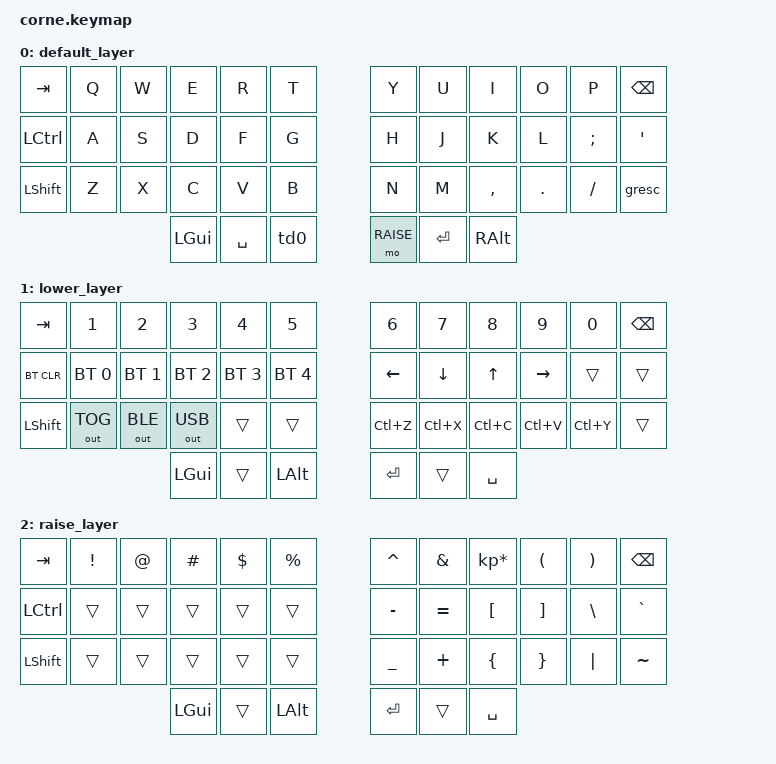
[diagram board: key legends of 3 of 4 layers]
/*
 * Copyright (c) 2020 The ZMK Contributors
 *
 * SPDX-License-Identifier: MIT
 */

#define DEFAULT 0
#define LOWER   1
#define RAISE   2
#define MOUSE   3

#include <behaviors.dtsi>
#include <dt-bindings/zmk/keys.h>
#include <dt-bindings/zmk/bt.h>
#include <dt-bindings/zmk/outputs.h>
#include <dt-bindings/zmk/mouse.h>


// -----------------------------------------------------------------------------------------
// |  0 | 1  | 2  | 3  | 4  | 5  |       | 6  |  7 | 8  | 9  | 10 | 11 |
// | 12 | 13 | 14 | 15 | 16 | 17 |       | 18 | 19 | 20 | 21 | 22 | 23 |
// | 24 | 25 | 26 | 27 | 28 | 29 |       | 30 | 31 | 32 | 33 | 34 | 35 |
//                | 36 | 37 | 38 |       | 39 | 40 | 41 |

/ {
    combos {
        compatible = "zmk,combos";
        combo_esc {
            timeout-ms = <50>;
            key-positions = <6 40>;
            bindings = <&tog MOUSE>;
        };
    };
};

/ {
        behaviors {
                td0: tap_dance_0 {
                        compatible = "zmk,behavior-tap-dance";
                        label = "TAP_DANCE_0";
                        #binding-cells = <0>;
                        tapping-term-ms = <200>;
                        bindings = <&mo LOWER>, <&mo MOUSE>, <&kp N3>;
                };
        };
    
    keymap {
                compatible = "zmk,keymap";

                default_layer {
// -----------------------------------------------------------------------------------------
// |  TAB |  Q  |  W  |  E  |  R  |  T  |       |  Y  |  U   |  I  |  O  |  P  | BKSP |
// | CTRL |  A  |  S  |  D  |  F  |  G  |       |  H  |  J   |  K  |  L  |  ;  |  '   |
// | SHFT |  Z  |  X  |  C  |  V  |  B  |       |  N  |  M   |  ,  |  .  |  /  | ESC  |
//                    | GUI | SPC | LWR |       | RSE | ENT  | ALT |
                        bindings = <
   &kp TAB   &kp Q &kp W &kp E &kp R &kp T       &kp Y &kp U  &kp I     &kp O   &kp P    &kp BSPC
   &kp LCTRL &kp A &kp S &kp D &kp F &kp G       &kp H &kp J  &kp K     &kp L   &kp SEMI &kp SQT
   &kp LSHFT &kp Z &kp X &kp C &kp V &kp B       &kp N &kp M  &kp COMMA &kp DOT &kp FSLH &gresc
		  &kp LGUI  &kp SPACE &td0       &mo RAISE &kp RET &kp RALT
                        >;
                };
                lower_layer {
// -----------------------------------------------------------------------------------------
// |  TAB |  1  |  2  |  3  |  4  |  5  |   |  6  |  7  |  8  |  9  |  0  | BKSP |
// | BTCLR| BT1 | BT2 | BT3 | BT4 | BT5 |   | LFT | DWN |  UP | RGT |     |      |
// | SHFT | TOG | BLE | USB |     |     |   |     |     |     |     |     |      |
//                    | GUI |     | ALT |   | ENT |     | SPC |
                        bindings = <
   &kp TAB    &kp N1       &kp N2       &kp N3       &kp N4       &kp N5         &kp N6   &kp N7   &kp N8 &kp N9    &kp N0 &kp BSPC
   &bt BT_CLR &bt BT_SEL 0 &bt BT_SEL 1 &bt BT_SEL 2 &bt BT_SEL 3 &bt BT_SEL 4   &kp LEFT &kp DOWN &kp UP &kp RIGHT &trans &trans
   &kp LSHFT  &out OUT_TOG &out OUT_BLE &out OUT_USB &trans       &trans         &kp LC(Z) &kp LC(X) &kp LC(C) &kp LC(V) &kp LC(Y) &trans
                          	        &kp LGUI     &trans       &kp LALT      &kp RET  &trans   &kp SPACE
                        >;
                };

                raise_layer {
// -----------------------------------------------------------------------------------------
// |  TAB |  !  |  @  |  #  |  $  |  %  |   |  ^  |  &  |  *  |  (  |  )  | BKSP |
// | CTRL |     |     |     |     |     |   |  -  |  =  |  [  |  ]  |  \  |  `   |
// | SHFT |     |     |     |     |     |   |  _  |  +  |  {  |  }  | "|" |  ~   |
//                    | GUI |     | ALT |   | ENT |     | SPC |
                        bindings = <
   &kp  TAB  &kp EXCL &kp AT &kp HASH &kp DLLR &kp PRCNT   &kp CARET &kp AMPS  &kp KP_MULTIPLY &kp LPAR &kp RPAR &kp BSPC
   &kp LCTRL &trans   &trans &trans   &trans   &trans      &kp MINUS &kp EQUAL &kp LBKT        &kp RBKT &kp BSLH &kp GRAVE
   &kp LSHFT &trans   &trans &trans   &trans   &trans      &kp UNDER &kp PLUS  &kp LBRC        &kp RBRC &kp PIPE &kp TILDE
                    	     &kp LGUI &trans   &kp LALT   &kp RET   &trans    &kp SPACE
                        >;
                };
		
		mouse_layer {
                        bindings = <
   &trans      &trans &kp LG(LBKT)      &mmv MOVE_UP        &kp LG(RBKT)        &trans                &none       &mwh SCROLL_UP    &none       &none       &none &none
   &trans      &trans &mmv MOVE_LEFT    &mmv MOVE_DOWN      &mmv MOVE_RIGHT     &trans                &none       &mkp LCLK         &mkp RCLK   &mkp MCLK   &none &none
   &trans      &trans &trans            &trans              &trans              &trans                &none       &mwh SCROLL_DOWN  &none       &none       &none
                          	             &kp LGUI      &trans      &none                &none     &trans      &none
                        
                        >;
                };
        };
};
